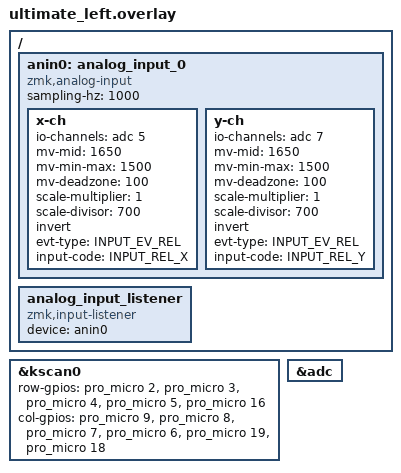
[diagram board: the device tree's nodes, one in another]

#include "ultimate.dtsi" // The shared dtsi file is included in the overlay
#include <zephyr/dt-bindings/input/input-event-codes.h>
#include <input/processors.dtsi>
/* Reference: https://docs.zephyrproject.org/apidoc/latest/group__input__events.html */



// Label of the kscan node in the dtsi
&kscan0 {
    row-gpios
            = <&pro_micro 2 (GPIO_ACTIVE_HIGH | GPIO_PULL_DOWN)>
            , <&pro_micro 3 (GPIO_ACTIVE_HIGH | GPIO_PULL_DOWN)>
            , <&pro_micro 4 (GPIO_ACTIVE_HIGH | GPIO_PULL_DOWN)>
            , <&pro_micro 5 (GPIO_ACTIVE_HIGH | GPIO_PULL_DOWN)>
            , <&pro_micro 16 (GPIO_ACTIVE_HIGH | GPIO_PULL_DOWN)>
            ;
    col-gpios
        = <&pro_micro 9 GPIO_ACTIVE_HIGH>
        , <&pro_micro 8 GPIO_ACTIVE_HIGH>
        , <&pro_micro 7 GPIO_ACTIVE_HIGH>
        , <&pro_micro 6 GPIO_ACTIVE_HIGH>
        , <&pro_micro 19 GPIO_ACTIVE_HIGH>
        , <&pro_micro 18 GPIO_ACTIVE_HIGH>
        ;
};

&adc {
	status = "okay";
};

/ {
	anin0: analog_input_0 {
		compatible = "zmk,analog-input";
		sampling-hz = <1000>;
		x-ch {
			io-channels = <&adc 5>; // 29 <--- see ain-map.png for nRF52840
			mv-mid = <1650>;
			mv-min-max = <1500>;
			mv-deadzone = <100>;
			scale-multiplier = <1>;
			scale-divisor = <700>;
			invert;
			evt-type = <INPUT_EV_REL>;
			input-code = <INPUT_REL_X>;
		};
		y-ch {
			io-channels = <&adc 7>; // 31 <--- see ain-map.png for nRF52840
			mv-mid = <1650>;
			mv-min-max = <1500>;
			mv-deadzone = <100>;
			scale-multiplier = <1>;
			scale-divisor = <700>;
			invert;
			evt-type = <INPUT_EV_REL>;
			input-code = <INPUT_REL_Y>;


		};
	};
    analog_input_listener {
        compatible = "zmk,input-listener";
        device = <&anin0>;
        
        // Maps X to HID Mouse X, Y to HID Mouse Y
        //input-processors = <&zip_xy_transform>;
    };
};


